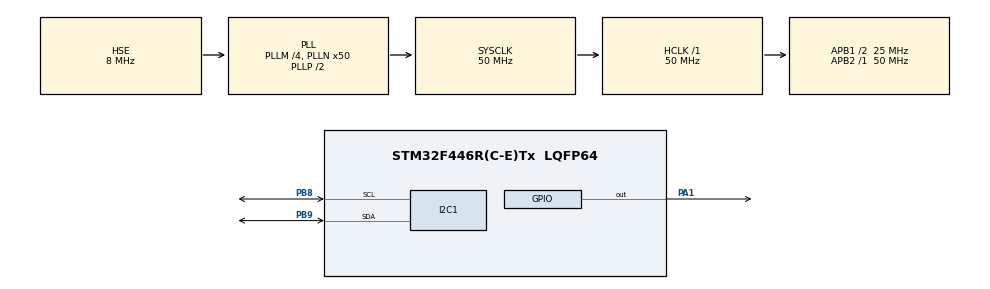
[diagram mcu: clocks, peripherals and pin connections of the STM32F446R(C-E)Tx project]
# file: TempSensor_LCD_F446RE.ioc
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Mcu.Family=STM32F4
Mcu.Name=STM32F446R(C-E)Tx
Mcu.Package=LQFP64
NVIC.PriorityGroup=NVIC_PRIORITYGROUP_4
PA1.Signal=GPIO_Output
PB8.Mode=I2C
PB8.Signal=I2C1_SCL
PB9.Mode=I2C
PB9.Signal=I2C1_SDA
PH0-OSC_IN.Mode=HSE-External-Oscillator
PH0-OSC_IN.Signal=RCC_OSC_IN
PH1-OSC_OUT.Mode=HSE-External-Oscillator
PH1-OSC_OUT.Signal=RCC_OSC_OUT
ProjectManager.HeapSize=0x200
ProjectManager.StackSize=0x400
ProjectManager.TargetToolchain=STM32CubeIDE
RCC.AHBFreq_Value=50000000
RCC.APB1CLKDivider=RCC_HCLK_DIV2
RCC.APB1Freq_Value=25000000
RCC.APB1TimFreq_Value=50000000
RCC.APB2Freq_Value=50000000
RCC.APB2TimFreq_Value=50000000
RCC.CortexFreq_Value=50000000
RCC.HCLKFreq_Value=50000000
RCC.HSE_VALUE=8000000
RCC.PLLM=4
RCC.PLLN=50
RCC.PLLSourceVirtual=RCC_PLLSOURCE_HSE
RCC.SYSCLKFreq_VALUE=50000000
RCC.SYSCLKSource=RCC_SYSCLKSOURCE_PLLCLK
RCC.USBFreq_Value=50000000
RCC.VCOOutputFreq_Value=100000000
TIM6.Prescaler=80-1
VP_TIM6_VS_ClockSourceINT.Mode=Enable_Timer
board=custom

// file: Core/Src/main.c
/* USER CODE BEGIN Header */
/**
  ******************************************************************************
  * @file           : main.c
  * @brief          : Main program body
  ******************************************************************************
  * @attention
  *
  * Copyright (c) 2025 STMicroelectronics.
  * All rights reserved.
  *
  * This software is licensed under terms that can be found in the LICENSE file
  * in the root directory of this software component.
  * If no LICENSE file comes with this software, it is provided AS-IS.
  *
  ******************************************************************************
  */
/* USER CODE END Header */
#include "main.h"

/* USER CODE BEGIN Includes */

#include "i2c-lcd.h"
#include "stdio.h"

/* USER CODE END Includes */

I2C_HandleTypeDef hi2c1;

TIM_HandleTypeDef htim6;

void SystemClock_Config(void);
static void MX_GPIO_Init(void);
static void MX_I2C1_Init(void);
static void MX_TIM6_Init(void);

/* USER CODE BEGIN 0 */

/* Function for Delay in Microseconds */
void delay_us(uint16_t time)
{
	__HAL_TIM_SET_COUNTER(&htim6, 0);
	while ((__HAL_TIM_GET_COUNTER(&htim6)) < time);
}

/* Function for displaying temperature on LCD */
void displayLCD_Temp (float temp)
{
	char str[20] = {0};
	lcd_put_cur(0, 0);

	sprintf(str, "TEMP: %.2f ", temp);
	lcd_send_string(str);
	lcd_send_data('C');
}

/* Function for displaying humidity on LCD */
void displayLCD_Rh (float rh)
{
	char str[20] = {0};
	lcd_put_cur(1, 0);

	sprintf(str, "HUMID: %.2f ", rh);
	lcd_send_string(str);
	lcd_send_data('%');
}

uint8_t intRh_data, decRh_data, intTemp_data, decTemp_data;
uint16_t RH, TEMP, CHECKSUM;

float DHT11_Temperature = 0;
float DHT11_Humidity = 0;
uint8_t sensorData = 0;

void Set_GPIO_Input (GPIO_TypeDef *GPIOx, uint16_t GPIO_Pin)
{
	GPIO_InitTypeDef GPIO_Struct = {0};
	GPIO_Struct.Pin = GPIO_Pin;
	GPIO_Struct.Mode = GPIO_MODE_INPUT;
	GPIO_Struct.Pull = GPIO_NOPULL;
	HAL_GPIO_Init(GPIOx, &GPIO_Struct);
}

void Set_GPIO_Output (GPIO_TypeDef *GPIOx, uint16_t GPIO_Pin)
{
	GPIO_InitTypeDef GPIO_Struct = {0};
	GPIO_Struct.Pin = GPIO_Pin;
	GPIO_Struct.Mode = GPIO_MODE_OUTPUT_PP;
	GPIO_Struct.Speed = GPIO_SPEED_FREQ_LOW;
	HAL_GPIO_Init(GPIOx, &GPIO_Struct);
}

/* DHT11 SENSOR CONFIGURATIONS */

#define DHT11_PORT GPIOA
#define DHT11_PIN GPIO_PIN_1

// When the signal starts, the MCU will pull the pin low for 18 milliseconds
// Then it will pull the pin high for 20 - 40 microseconds
// Finally, the MCU will release the pin
void MCU_StartSignal (void)
{
	HAL_GPIO_WritePin(GPIOA, GPIO_PIN_1, 1);
	HAL_Delay(300);

	Set_GPIO_Output(DHT11_PORT, DHT11_PIN);				// set PortA Pin1 as output
	HAL_GPIO_WritePin(DHT11_PORT, DHT11_PIN, 0);		// set bit 0 to pull pin LOW
	HAL_Delay(18);										// delay for 18 milliseconds
	HAL_GPIO_WritePin(DHT11_PORT, DHT11_PIN, 1);		// set bit 1 to pull pin HIGH
	delay_us(20);										// delay for 20 microseconds
	Set_GPIO_Input(DHT11_PORT, DHT11_PIN);				// finally set PortA Pin1 as input
}

uint8_t DHT11_CheckSignal (void)
{
	uint8_t Response_Signal = 0;
	delay_us(40);										// wait for 40 microseconds
	if (!(HAL_GPIO_ReadPin(DHT11_PORT, DHT11_PIN))) {
		delay_us(80);									// delay for 80 microseconds
		if (HAL_GPIO_ReadPin(DHT11_PORT, DHT11_PIN)) {	// check if the pin is HIGH
			Response_Signal = 1;						// if so, the signal is 1 (present)
		} else {
			Response_Signal = -1;						// else, the signal is -1 (not present)
		}
	}
	while (HAL_GPIO_ReadPin(DHT11_PORT, DHT11_PIN));	// wait for pin to go LOW

	return Response_Signal;
}

uint8_t DHT11_ReadSignal (void)
{
	uint8_t data_bit, count;

	for (count = 0; count < 8; count++) {
		while (!(HAL_GPIO_ReadPin(DHT11_PORT, DHT11_PIN))); // wait for the pin to go HIGH
		delay_us(40);										// delay for 40 microseconds

		if (!(HAL_GPIO_ReadPin(DHT11_PORT, DHT11_PIN))) {	// if the pin is low
			data_bit &= ~(1 << (7 - count));				// set the bit 0
		} else {
			data_bit |= (1 << (7 - count));					// else, set the bit 1
		}

		while (HAL_GPIO_ReadPin(DHT11_PORT, DHT11_PIN));	// wait for the pin to go LOW
	}
	return data_bit;
}

/* USER CODE END 0 */

int main(void)
{

  /* MCU Configuration--------------------------------------------------------*/

  /* Reset of all peripherals, Initializes the Flash interface and the Systick. */
  HAL_Init();

  /* Configure the system clock */
  SystemClock_Config();

  /* Initialize all configured peripherals */
  MX_GPIO_Init();
  MX_I2C1_Init();
  MX_TIM6_Init();
  /* USER CODE BEGIN 2 */

  HAL_TIM_Base_Start(&htim6);

  lcd_init();
  lcd_send_string("WELCOME TO STM32");
  HAL_Delay(3000);
  lcd_clear();

  /* USER CODE END 2 */

  /* Infinite loop */
  /* USER CODE BEGIN WHILE */
  while (1)
  {

	  // Data format in correct order: 8bit integral RH data + 8bit decimal RH data + 8bit integral T data
	  // + 8bit decimal T data + 8bit check sum.
	  MCU_StartSignal();
	  sensorData = DHT11_CheckSignal();
	  intRh_data = DHT11_ReadSignal();
	  decRh_data = DHT11_ReadSignal();
	  intTemp_data = DHT11_ReadSignal();
	  decTemp_data = DHT11_ReadSignal();
	  CHECKSUM = DHT11_ReadSignal();

	  TEMP = intTemp_data;
	  RH = intRh_data;

	  DHT11_Temperature = (float) TEMP;
	  DHT11_Humidity = (float) RH;

	  displayLCD_Temp(DHT11_Temperature);
	  displayLCD_Rh(DHT11_Humidity);

	  HAL_Delay(4000);

    /* USER CODE END WHILE */

  }
}

void SystemClock_Config(void)
{
  RCC_OscInitTypeDef RCC_OscInitStruct = {0};
  RCC_ClkInitTypeDef RCC_ClkInitStruct = {0};

  /** Configure the main internal regulator output voltage
  */
  __HAL_RCC_PWR_CLK_ENABLE();
  __HAL_PWR_VOLTAGESCALING_CONFIG(PWR_REGULATOR_VOLTAGE_SCALE3);

  /** Initializes the RCC Oscillators according to the specified parameters
  * in the RCC_OscInitTypeDef structure.
  */
  RCC_OscInitStruct.OscillatorType = RCC_OSCILLATORTYPE_HSE;
  RCC_OscInitStruct.HSEState = RCC_HSE_ON;
  RCC_OscInitStruct.PLL.PLLState = RCC_PLL_ON;
  RCC_OscInitStruct.PLL.PLLSource = RCC_PLLSOURCE_HSE;
  RCC_OscInitStruct.PLL.PLLM = 4;
  RCC_OscInitStruct.PLL.PLLN = 50;
  RCC_OscInitStruct.PLL.PLLP = RCC_PLLP_DIV2;
  RCC_OscInitStruct.PLL.PLLQ = 2;
  RCC_OscInitStruct.PLL.PLLR = 2;
  if (HAL_RCC_OscConfig(&RCC_OscInitStruct) != HAL_OK)
  {
    Error_Handler();
  }

  /** Initializes the CPU, AHB and APB buses clocks
  */
  RCC_ClkInitStruct.ClockType = RCC_CLOCKTYPE_HCLK|RCC_CLOCKTYPE_SYSCLK
                              |RCC_CLOCKTYPE_PCLK1|RCC_CLOCKTYPE_PCLK2;
  RCC_ClkInitStruct.SYSCLKSource = RCC_SYSCLKSOURCE_PLLCLK;
  RCC_ClkInitStruct.AHBCLKDivider = RCC_SYSCLK_DIV1;
  RCC_ClkInitStruct.APB1CLKDivider = RCC_HCLK_DIV2;
  RCC_ClkInitStruct.APB2CLKDivider = RCC_HCLK_DIV1;

  if (HAL_RCC_ClockConfig(&RCC_ClkInitStruct, FLASH_LATENCY_1) != HAL_OK)
  {
    Error_Handler();
  }
}

static void MX_I2C1_Init(void)
{

  hi2c1.Instance = I2C1;
  hi2c1.Init.ClockSpeed = 100000;
  hi2c1.Init.DutyCycle = I2C_DUTYCYCLE_2;
  hi2c1.Init.OwnAddress1 = 0;
  hi2c1.Init.AddressingMode = I2C_ADDRESSINGMODE_7BIT;
  hi2c1.Init.DualAddressMode = I2C_DUALADDRESS_DISABLE;
  hi2c1.Init.OwnAddress2 = 0;
  hi2c1.Init.GeneralCallMode = I2C_GENERALCALL_DISABLE;
  hi2c1.Init.NoStretchMode = I2C_NOSTRETCH_DISABLE;
  if (HAL_I2C_Init(&hi2c1) != HAL_OK)
  {
    Error_Handler();
  }

}

static void MX_TIM6_Init(void)
{

  TIM_MasterConfigTypeDef sMasterConfig = {0};

  htim6.Instance = TIM6;
  htim6.Init.Prescaler = 80-1;
  htim6.Init.CounterMode = TIM_COUNTERMODE_UP;
  htim6.Init.Period = 65535;
  htim6.Init.AutoReloadPreload = TIM_AUTORELOAD_PRELOAD_DISABLE;
  if (HAL_TIM_Base_Init(&htim6) != HAL_OK)
  {
    Error_Handler();
  }
  sMasterConfig.MasterOutputTrigger = TIM_TRGO_RESET;
  sMasterConfig.MasterSlaveMode = TIM_MASTERSLAVEMODE_DISABLE;
  if (HAL_TIMEx_MasterConfigSynchronization(&htim6, &sMasterConfig) != HAL_OK)
  {
    Error_Handler();
  }

}

static void MX_GPIO_Init(void)
{
  GPIO_InitTypeDef GPIO_InitStruct = {0};

  /* GPIO Ports Clock Enable */
  __HAL_RCC_GPIOH_CLK_ENABLE();
  __HAL_RCC_GPIOA_CLK_ENABLE();
  __HAL_RCC_GPIOB_CLK_ENABLE();

  /*Configure GPIO pin Output Level */
  HAL_GPIO_WritePin(GPIOA, GPIO_PIN_1, GPIO_PIN_RESET);

  /*Configure GPIO pin : PA1 */
  GPIO_InitStruct.Pin = GPIO_PIN_1;
  GPIO_InitStruct.Mode = GPIO_MODE_OUTPUT_PP;
  GPIO_InitStruct.Pull = GPIO_NOPULL;
  GPIO_InitStruct.Speed = GPIO_SPEED_FREQ_LOW;
  HAL_GPIO_Init(GPIOA, &GPIO_InitStruct);

}

void Error_Handler(void)
{
  __disable_irq();
  while (1)
  {
  }
}
